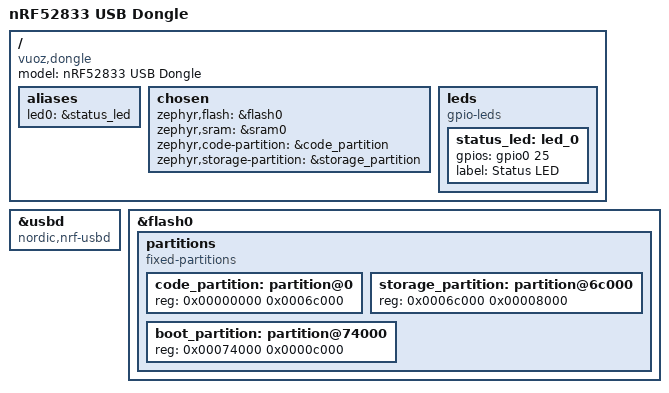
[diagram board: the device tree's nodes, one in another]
/*
 * Copyright (c) 2021 The ZMK Contributors
 *
 * SPDX-License-Identifier: MIT
 */
/dts-v1/;

#include <nordic/nrf52833_qiaa.dtsi>
#include <common/nordic/nrf52833_uf2_boot_mode.dtsi>

/ {
	model = "nRF52833 USB Dongle";
	compatible = "vuoz,dongle", "nordic,nrf52833-qiaa";

	aliases {
		led0 = &status_led;
	};
    chosen {
        zephyr,flash = &flash0;
        zephyr,sram = &sram0;
        zephyr,code-partition = &code_partition;
        zephyr,storage-partition = &storage_partition;
    };


	leds {
		compatible = "gpio-leds";
		status_led: led_0 {
			gpios = <&gpio0 25 GPIO_ACTIVE_HIGH>;
			label = "Status LED";
		};
	};
};

zephyr_udc0: &usbd {
	compatible = "nordic,nrf-usbd";
	status = "okay";
};

&flash0 {
    /*
     * For more information, see:
     * http://docs.zephyrproject.org/latest/devices/dts/flash_partitions.html
     */
    partitions {
        compatible = "fixed-partitions";
        #address-cells = <1>;
        #size-cells = <1>;

        code_partition: partition@0 {
            reg = <0x00000000 0x0006c000>;
        };

        /*
         * The flash starting at 0x0006c000 and ending at
         * 0x00073fff is reserved for use by the application.
         */

        /*
         * Storage partition will be used by FCB/LittleFS/NVS
         * if enabled.
         */
        storage_partition: partition@6c000 {
            reg = <0x0006c000 0x00008000>;
        };

        boot_partition: partition@74000 {
            reg = <0x00074000 0x0000c000>;
        };
    };
};

